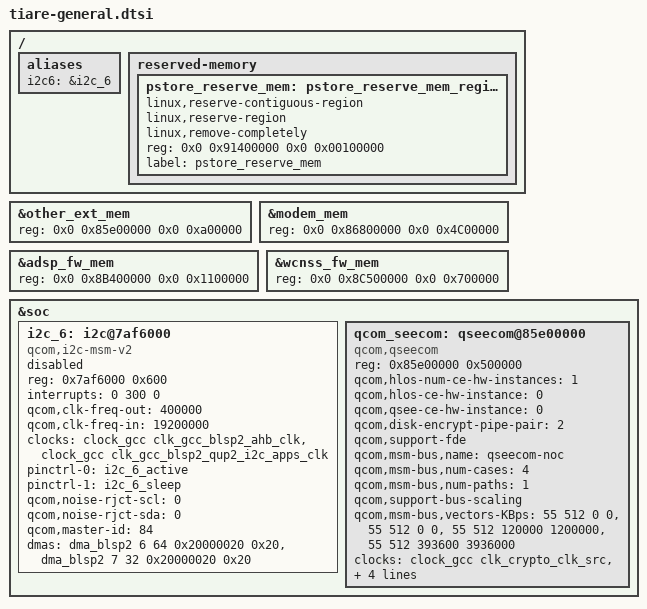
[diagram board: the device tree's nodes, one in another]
/ {
	aliases {
		/delete-property/ spi7;
		i2c6 = &i2c_6;
	};
};

&other_ext_mem {
	reg = <0x0 0x85e00000 0x0 0xa00000>;
};

&modem_mem {
	reg = <0x0 0x86800000 0x0 0x4C00000>;
};

&adsp_fw_mem {
	reg = <0x0 0x8B400000 0x0 0x1100000>;
};

&wcnss_fw_mem {
	reg = <0x0 0x8C500000 0x0 0x700000>;
};

/ {
	reserved-memory {
		pstore_reserve_mem: pstore_reserve_mem_region@0 {
			linux,reserve-contiguous-region;
			linux,reserve-region;
			linux,remove-completely;
			reg = <0x0 0x91400000 0x0 0x00100000>;
			label = "pstore_reserve_mem";
                };
	};
};

&soc {
	i2c_6: i2c@7af6000 { /* BLSP2 QUP1 */
		compatible = "qcom,i2c-msm-v2";
		#address-cells = <1>;
		#size-cells = <0>;
		reg-names = "qup_phys_addr";
		reg = <0x7af6000 0x600>;
		interrupt-names = "qup_irq";
		interrupts = <0 300 0>;
		qcom,clk-freq-out = <400000>;
		qcom,clk-freq-in  = <19200000>;
		clock-names = "iface_clk", "core_clk";
		clocks = <&clock_gcc clk_gcc_blsp2_ahb_clk>,
			<&clock_gcc clk_gcc_blsp2_qup2_i2c_apps_clk>;

		pinctrl-names = "i2c_active", "i2c_sleep";
		pinctrl-0 = <&i2c_6_active>;
		pinctrl-1 = <&i2c_6_sleep>;
		qcom,noise-rjct-scl = <0>;
		qcom,noise-rjct-sda = <0>;
		qcom,master-id = <84>;
		dmas = <&dma_blsp2 6 64 0x20000020 0x20>,
			<&dma_blsp2 7 32 0x20000020 0x20>;
		dma-names = "tx", "rx";
		status = "disabled";
	};
};

&soc {
	/delete-node/ qseecom@84A00000;
	qcom_seecom: qseecom@85e00000 {
		compatible = "qcom,qseecom";
		reg = <0x85e00000 0x500000>;
		reg-names = "secapp-region";
		qcom,hlos-num-ce-hw-instances = <1>;
		qcom,hlos-ce-hw-instance = <0>;
		qcom,qsee-ce-hw-instance = <0>;
		qcom,disk-encrypt-pipe-pair = <2>;
		qcom,support-fde;
		qcom,msm-bus,name = "qseecom-noc";
		qcom,msm-bus,num-cases = <4>;
		qcom,msm-bus,num-paths = <1>;
		qcom,support-bus-scaling;
		qcom,msm-bus,vectors-KBps =
			<55 512 0 0>,
			<55 512 0 0>,
			<55 512 120000 1200000>,
			<55 512 393600 3936000>;
		clocks = <&clock_gcc clk_crypto_clk_src>,
			<&clock_gcc clk_gcc_crypto_clk>,
			<&clock_gcc clk_gcc_crypto_ahb_clk>,
			<&clock_gcc clk_gcc_crypto_axi_clk>;
		clock-names = "core_clk_src", "core_clk",
			"iface_clk", "bus_clk";
		qcom,ce-opp-freq = <100000000>;
	};
};
